# STM32H7S register map
File version: 1.3
CPU: CM7 r0p1, little endian, MPU, FPU, 4 interrupt priority bits
Registers are 32-bit, read-write, reset 0x0 unless marked. A register's access mark holds for its fields unless they carry their own. Offsets are from the block's base; [hi:lo] are bit positions; lines under a group give offsets from that group; {n}, {i} and the like mark numbered series; 'fields as' and 'values as' point back to an identical list; <NAME> marks a mode.

## HPDMA — High-performance direct memory access controller
Base 0x52000000
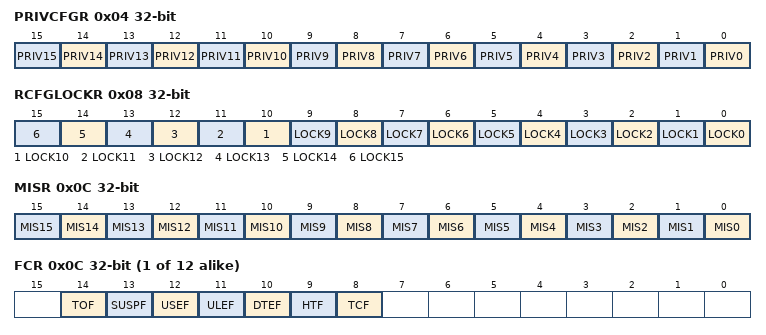
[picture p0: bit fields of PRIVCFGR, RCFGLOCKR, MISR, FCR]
0x04 PRIVCFGR — HPDMA privileged configuration register
  [n] PRIV{n} (n=0..15) — privileged state of channel x
0x08 RCFGLOCKR — HPDMA configuration lock register
  [n] LOCK{n} (n=0..15) — lock the configuration of HPDMA_PRIVCFGR.PRIVx until a global HPDMA reset This bit is cleared after reset and, once set, it cannot be reset until a global HPDMA reset.
0x0C MISR ro — HPDMA masked interrupt status register
  [n] MIS{n} (n=0..15) — masked interrupt status of channel x
{0x50+0x80*i} CH{i} (i=0..11) group — Channel cluster
  0x00 LBAR — HPDMA channel 0 linked-list base address register
    [31:16] LBA — linked-list base address of HPDMA channel x
  0x0C FCR wo — HPDMA channel 0 flag clear register
    [14] TOF — trigger overrun flag clear
    [13] SUSPF — completed suspension flag clear
    [12] USEF — user setting error flag clear
    [11] ULEF — update link transfer error flag clear
    [10] DTEF — data transfer error flag clear
    [9] HTF — half transfer flag clear
    [8] TCF — transfer complete flag clear
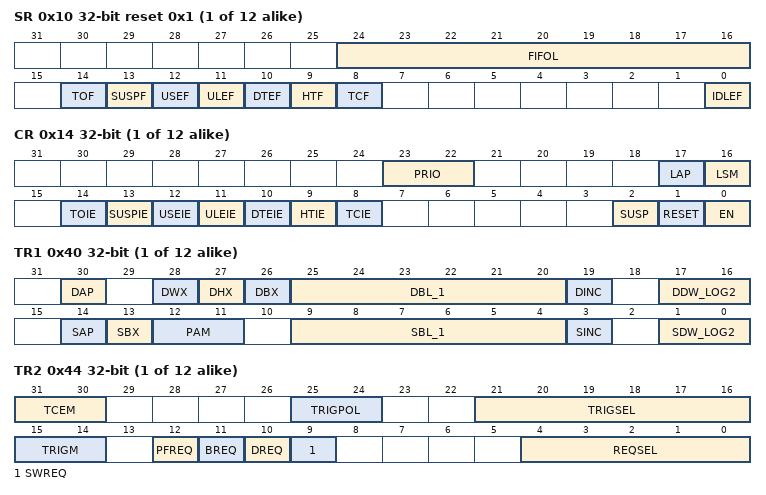
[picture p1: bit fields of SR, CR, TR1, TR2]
  0x10 SR ro reset 0x1 — HPDMA channel 0 status register
    [24:16] FIFOL — monitored FIFO level
    [14] TOF — trigger overrun flag
    [13] SUSPF — completed suspension flag
    [12] USEF — user setting error flag
    [11] ULEF — update link transfer error flag
    [10] DTEF — data transfer error flag
    [9] HTF — half transfer flag An half transfer event is either an half block transfer or an half 2D/repeated block transfer, depending on the transfer complete event mode (HPDMA_CxTR2.TCEM[1:0]). An half block transfer occurs when half of the bytes of the source block size (rounded up integer of HPDMA_CxBR1.BNDT[15:0]/2) has been transferred to the destination. An half 2D/repeated block transfer occurs when half of the repeated blocks (rounded up integer of (HPDMA_CxBR1.BRC[10:0]+1)/2)) has been transferred to the destination.
    [8] TCF — transfer complete flag A transfer complete event is either a block transfer complete, a 2D/repeated block transfer complete, a LLI transfer complete including the upload of the next LLI if any, or the full linked-list completion, depending on the transfer complete event mode (HPDMA_CxTR2.TCEM[1:0]).
    [0] IDLEF — idle flag This idle flag is de-asserted by hardware when the channel is enabled (HPDMA_CxCR.EN = 1) with a valid channel configuration (no USEF to be immediately reported). This idle flag is asserted after hard reset or by hardware when the channel is back in idle state (in suspended or disabled state).
  0x14 CR access per field — HPDMA channel 0 control register
    [23:22] PRIO rw — priority level of the channel x HPDMA transfer versus others Note: This bit must be written when EN = 0. This bit is read-only when EN = 1.
    [17] LAP rw — linked-list allocated port This bit is used to allocate the master port for the update of the HPDMA linked-list registers from the memory. Note: This bit must be written when EN=0. This bit is read-only when EN=1.
    [16] LSM rw — Link step mode First the (possible 1D/repeated) block transfer is executed as defined by the current internal register file until HPDMA_CxBR1.BNDT[15:0] = 0 and HPDMA_CxBR1.BRC[10:0] = 0 if present. Secondly the next linked-list data structure is conditionally uploaded from memory as defined by HPDMA_CxLLR. Then channel execution is completed. Note: This bit must be written when EN = 0. This bit is read-only when EN = 1.
    [14] TOIE rw — trigger overrun interrupt enable
    [13] SUSPIE rw — completed suspension interrupt enable
    [12] USEIE rw — user setting error interrupt enable
    [11] ULEIE rw — update link transfer error interrupt enable
    [10] DTEIE rw — data transfer error interrupt enable
    [9] HTIE rw — half transfer complete interrupt enable
    [8] TCIE rw — transfer complete interrupt enable
    [2] SUSP rw — suspend Writing 1 into the field RESET (bit 1) causes the hardware to de-assert this bit, whatever is written into this bit 2. Else: Software must write 1 in order to suspend an active channel (a channel with an ongoing HPDMA transfer over its master ports). The software must write 0 in order to resume a suspended channel, following the programming sequence detailed in Figure 158.
    [1] RESET wo — reset This bit is write only. Writing 0 has no impact. Writing 1 implies the reset of the following: the FIFO, the channel internal state, SUSP and EN bits (whatever is written receptively in bit 2 and bit 0). The reset is effective when the channel is in steady state, meaning one of the following: - active channel in suspended state (HPDMA_CxSR.SUSPF = 1 and HPDMA_CxSR.IDLEF = HPDMA_CxCR.EN = 1) - channel in disabled state (HPDMA_CxSR.IDLEF = 1 and HPDMA_CxCR.EN = 0). After writing a RESET, to continue using this channel, the user must explicitly reconfigure the channel including the hardware-modified configuration registers (HPDMA_CxBR1, HPDMA_CxSAR and HPDMA_CxDAR) before enabling again the channel (see the programming sequence in Figure 159).
    [0] EN rw — enable Writing 1 into the field RESET (bit 1) causes the hardware to de-assert this bit, whatever is written into this bit 0. Else: this bit is de-asserted by hardware when there is a transfer error (master bus error or user setting error) or when there is a channel transfer complete (channel ready to be configured, for example if LSM = 1 at the end of a single execution of the LLI). Else, this bit can be asserted by software. Writing 0 into this EN bit is ignored.
  0x40 TR1 — HPDMA channel 0 transfer register 1
    [30] DAP — destination allocated port This bit is used to allocate the master port for the destination transfer Note: This bit must be written when EN = 0. This bit is read-only when EN = 1.
    [28] DWX — destination word exchange If the destination data size is not a double-word, this bit is ignored. If the destination data size is a double-word and if destination bus is AXI (DAP = 0):
    [27] DHX — destination half-word exchange If the destination data size is shorter than a word, this bit is ignored. If the destination data size is a word or double-word and if destination bus is AXI (DAP = 0):
    [26] DBX — destination byte exchange If the destination data size is a byte, this bit is ignored. If the destination data size is not a byte:
    [25:20] DBL_1 — destination burst length minus 1, between 0 and 63 The burst length unit is one data named beat within a burst. If DBL_1[5:0] =0 , the burst can be named as single. Each data/beat has a width defined by the destination data width DDW_LOG2[1:0]. Note: If a burst transfer crossed a 1- or 4-Kbyte address boundary on respectively an AHB or AXI transfer, the HPDMA modifies and shortens the programmed burst into singles or bursts of lower length, to be compliant with the AHB/AXI protocol. Note: If the burst length exceeds 16 on an AHB transfer, or if the burst on an AXI transfer is both with fixed addressing (DINC = 0) and with a burst length which exceeds 16, the HPDMA modifies and shortens the programmed burst into bursts of lower length, to be compliant with the AHB or AXI protocol. Note: If a burst transfer is of length greater than the FIFO size of the channel x, the HPDMA modifies and shortens the programmed burst into singles or bursts of lower length, to be compliant with the FIFO size. Transfer performance is lower, with HPDMA re-arbitration between effective and lower singles/bursts, but the data integrity is guaranteed.
    [19] DINC — destination incrementing burst The destination address, pointed by HPDMA_CxDAR, is kept constant after a burst beat/single transfer, or is incremented by the offset value corresponding to a contiguous data after a burst beat/single transfer.
    [17:16] DDW_LOG2 — binary logarithm of the destination data width of a burst, in bytes if DAP = 1, user setting error reported and no transfer issued Note: A burst with a double-word data width must be allocated to the AXI master port, else a user setting error is reported and none transfer is issued. Note: A destination burst transfer must have an aligned address with its data width (start address HPDMA_CxDAR[2:0] and address offset HPDMA_CxTR3.DAO[2:0], versus DDW_LOG2[1:0]). Otherwise a user setting error is reported and no transfer is issued. Note: When configured in packing mode (PAM[1] = 1 and destination data width different from source data width), a source block size must be a multiple of the destination data width (see HPDMA_CxBR1.BNDT[2:0] vs DDW_LOG2[1:0]). Else a user setting error is reported and none transfer is issued.
    [14] SAP — source allocated port This bit is used to allocate the master port for the source transfer Note: This bit must be written when EN = 0. This bit is read-only when EN = 1.
    [13] SBX — source byte exchange within the unaligned half-word of each source word If the source data width is shorter than a word, this bit is ignored. If the source data width is a word or a double-word, and if source bus is AXI (SAP = 0):
    [12:11] PAM — padding/alignment mode If DDW_LOG2[1:0] = SDW_LOG2[1:0]: if the data width of a burst destination transfer is equal to the data width of a burst source transfer, these bits are ignored. Else, in the following enumerated values, the condition PAM_1 is when destination data width is higher that source data width, and the condition PAM_2 is when destination data width is higher than source data width. Note: If the transfer from the source peripheral is configured with peripheral flow-control mode (SWREQ = 0 and PFREQ = 1 and DREQ = 0), and if the destination data width > the source data width, packing is not supported.
    [9:4] SBL_1 — source burst length minus 1, between 0 and 63 The burst length unit is one data named beat within a burst. If SBL_1[5:0] =0 , the burst can be named as single. Each data/beat has a width defined by the destination data width SDW_LOG2[1:0]. Note: If a burst transfer crossed a 1- or 4-Kbyte address boundary on respectively an AHB or an AXI transfer, the HPDMA modifies and shortens the programmed burst into singles or bursts of lower length, to be compliant with the AHB protocol. Note: If the burst length exceeds 16 on a AHB transfer, or if the burst on a AXI transfer is both with fixed addressing (SINC=0) and with a burst length which exceeds 16, the HPDMA modifies and shortens the programmed burst into singles or bursts of lower length, to be compliant with the FIFO size. Transfer performance is lower, with HPDMA re-arbitration between effective and lower singles/bursts, but the data integrity is guaranteed.
    [3] SINC — source incrementing burst The source address, pointed by HPDMA_CxSAR, is kept constant after a burst beat/single transfer or is incremented by the offset value corresponding to a contiguous data after a burst beat/single transfer.
    [1:0] SDW_LOG2 — binary logarithm of the source data width of a burst in bytes if SAP = 1, user setting error reported and no transfer issued Note: A burst with a double-word data width must be allocated to the AXI master port, else a user setting error is reported and none transfer is issued. A source block size must be a multiple of the source data width (HPDMA_CxBR1.BNDT[2:0] versus SDW_LOG2[1:0]). Otherwise, a user setting error is reported and no transfer is issued. Note: A source burst transfer must have an aligned address with its data width (start address HPDMA_CxSAR[2:0] versus SDW_LOG2[1:0]). Otherwise, a user setting error is reported and none transfer is issued.
  0x44 TR2 — HPDMA channel 0 transfer register 2
    [31:30] TCEM — transfer complete event mode These bits define the transfer granularity for the transfer complete and half transfer complete events generation. Note: If the initial LLI<sub>0 </sub>data transfer is null/void (directly programmed by the internal register file with HPDMA_CxBR1.BNDT[15:0] = 0), then neither the complete transfer event nor the half transfer event is generated. Note: If the initial LLI<sub>0 </sub>data transfer is null/void (directly programmed by the internal register file with HPDMA_CxBR1.BNDT[15:0] = 0), then neither the complete transfer event nor the half transfer event is generated. Note: If the initial LLI<sub>0 </sub>data transfer is null/void (directly programmed by the internal register file with HPDMA_CxBR1.BNDT[15:0] = 0), then the half transfer event is not generated, and the transfer complete event is generated when is completed the loading of the LLI<sub>1</sub>.
    [25:24] TRIGPOL — trigger event polarity These bits define the polarity of the selected trigger event input defined by TRIGSEL[5:0].
    [21:16] TRIGSEL — trigger event input selection These bits select the trigger event input of the HPDMA transfer (as per Section 27.3.6), with an active trigger event if TRIGPOL[1:0] different from 00.
    [15:14] TRIGM — trigger mode These bits define the transfer granularity for its conditioning by the trigger. If the channel x is enabled (HPDMA_CxCR.EN asserted) with TRIGPOL[1:0] = 00 or 11, these TRIGM[1:0] bits are ignored. Else, an HPDMA transfer is conditioned by at least one trigger hit: first burst read of a 2D/repeated block transfer is conditioned by one hit trigger. If the peripheral is programmed as a source (DREQ = 0) of the LLI data transfer, each programmed burst read is conditioned. If the peripheral is programmed as a destination (DREQ = 1) of the LLI data transfer, each programmed burst write is conditioned. The first memory burst read of a (possibly 2D/repeated) block, also named as the first ready FIFO-based source burst, is gated by the occurrence of both the hardware request and the first trigger hit. The HPDMA monitoring of a trigger for channel x is started when the channel is enabled/loaded with a new active trigger configuration: rising or falling edge on a selected trigger (TRIGPOL[1:0] = 01 or respectively TRIGPOL[1:0] = 10). The monitoring of this trigger is kept active during the triggered and uncompleted (data or link) transfer; and if a new trigger is detected then, this hit is internally memorized to grant the next transfer, as long as the defined rising or falling edge is not modified, and the TRIGSEL[5:0] is not modified, and the channel is enabled. Transferring a next LLI<sub>n+1</sub> that updates the HPDMA_CxTR2 with a new value for any of TRIGSEL[5:0] or TRIGPOL[1:0], resets the monitoring, trashing the memorized hit of the formerly defined LLI<sub>n </sub>trigger. After a first new trigger hit<sub>n+1</sub> is memorized, if another second trigger hit<sub>n+2</sub> is detected and if the hit<sub>n</sub> triggered transfer is still not completed, hit<sub>n+2 </sub>is lost and not memorized.memorized. A trigger overrun flag is reported (HPDMA_CxSR.TOF =1 ), and an interrupt is generated if enabled (HPDMA_CxCR.TOIE = 1). The channel is not automatically disabled by hardware due to a trigger overrun. Note: When the source block size is not a multiple of the source burst size and is a multiple of the source data width, then the last programmed source burst is not completed and is internally shorten to match the block size. In this case, if TRIGM[1:0] = 11 and (SWREQ =1 or (SWREQ = 0 and DREQ =0 )), the shortened burst transfer (by singles or/and by bursts of lower length) is conditioned once by the trigger. Note: When the programmed destination burst is internally shortened by singles or/and by bursts of lower length (versus FIFO size, versus block size, 1/4-Kbyte boundary address crossing maximum burst length vs AHB/AXI protocol): if the trigger is conditioning the programmed destination burst (if TRIGM[1:0] = 11 and SWREQ = 0 and DREQ = 1), this shortened destination burst transfer is conditioned once by the trigger.
    [12] PFREQ — Hardware request in peripheral flow control mode Important: If a given channel x is not implemented with this feature, this bit is reserved and PFREQ is not present (see Section 27.3.5 for the list of the implemented channels with this feature. If the channel x is activated (HPDMA_CxCR.EN asserted) with SWREQ = 1 (software request for a memory-to-memory transfer), this bit is ignored. Else: Note: In peripheral flow control mode, there are the following restrictions: Note: - no 2D/repeated block support (HPDMA_CxBR1.BRC[10:0] must be set to 0 if present) Note: - the peripheral must be set as the source of the transfer (DREQ = 0). Note: - data packing to a wider destination width is not supported (if destination width > source data width, HPDMA_CxTR1.PAM[1] must be set to 0). Note: - HPDMA_CxBR1.BNDT[15:0] must be set as a multiple of the source (peripheral) burst size.
    [11] BREQ — Block hardware request If the channel x is activated (HPDMA_CxCR.EN asserted) with SWREQ = 1 (software request for a memory-to-memory transfer), this bit is ignored. Else:
    [10] DREQ — destination hardware request This bit is ignored if channel x is activated (HPDMA_CxCR.EN asserted) with SWREQ = 1 (software request for a memory-to-memory transfer). Else: Note: If the channel x is activated (HPDMA_CxCR.EN is asserted) with SWREQ = 0 and PFREQ = 1 (peripheral hardware request with peripheral flow-control mode), any software assertion to this DREQ bit is ignored: in peripheral flow-control mode, only a peripheral-to-memory transfer is supported.
    [9] SWREQ — software request This bit is internally taken into account when HPDMA_CxCR.EN is asserted.
    [4:0] REQSEL — hardware request selection These bits are ignored if channel x is activated (HPDMA_CxCR.EN asserted) with SWREQ = 1 (software request for a memory-to-memory transfer). Else, the selected hardware request is internally taken into account as per Section 27.3.3. The user must not assign a same input hardware request (same REQSEL[4:0] value) to different active HPDMA channels (HPDMA_CxCR.EN = 1 and HPDMA_CxTR2.SWREQ = 0 for these channels). The HPDMA is not intended to hardware support the case of simultaneous enabled channels incorrectly configured with a same hardware peripheral request signal, and there is no user setting error reporting.
  0x48 BR1 — HPDMA channel 0 block register 1
    [15:0] BNDT — block number of data bytes to transfer from the source Block size transferred from the source. When the channel is enabled, this field becomes read-only and is decremented, indicating the remaining number of data items in the current source block to be transferred. BNDT[15:0] is programmed in number of bytes, maximum source block size is 64 Kbytes -1. Once the last data transfer is completed (BNDT[15:0] = 0): - if HPDMA_CxLLR.UB1 = 1, this field is updated by the LLI in the memory. - if HPDMA_CxLLR.UB1 = 0 and if there is at least one non null Uxx update bit, this field is internally restored to the programmed value. - if all HPDMA_CxLLR.Uxx = 0 and if HPDMA_CxLLR.LA[15:0] = 0, this field is internally restored to the programmed value (infinite/continuous last LLI). - if HPDMA_CxLLR = 0, this field is kept as zero following the last LLI data transfer. Note: A non-null source block size must be a multiple of the source data width (BNDT[2:0] versus HPDMA_CxTR1.SDW_LOG2[1:0]). Else a user setting error is reported and no transfer is issued. Note: When configured in packing mode (HPDMA_CxTR1.PAM[1] = 1 and destination data width different from source data width), a non-null source block size must be a multiple of the destination data width (BNDT[2:0] versus HPDMA_CxTR1.DDW_LOG2[1:0]). Else a user setting error is reported and no transfer is issued.
  0x4C SAR — HPDMA channel 0 source address register
    [31:0] SA — source address This field is the pointer to the address from which the next data is read. During the channel activity, depending on the source addressing mode (HPDMA_CxTR1.SINC), this field is kept fixed or incremented by the data width (HPDMA_CxTR1.SDW_LOG2[1:0]) after each burst source data, reflecting the next address from which data is read. During the channel activity, this address is updated after each completed source burst, consequently to: the programmed source burst; either in fixed addressing mode or in contiguous-data incremented mode. If contiguously incremented (HPDMA_CxTR1.SINC = 1), then the additional address offset value is the programmed burst size, as defined by HPDMA_CxTR1.SBL_1[5:0] and HPDMA_CxTR1.SDW_LOG2[21:0] the additional source incremented/decremented offset value as programmed by HPDMA_CxBR1.SDEC and HPDMA_CxTR3.SAO[12:0] once/if completed source block transfer, for a channel x with 2D addressing capability (x = 12 to 15). additional block repeat source incremented/decremented offset value as programmed by HPDMA_CxBR1.BRSDEC and HPDMA_CxBR2.BRSAO[15:0] In linked-list mode, after a LLI data transfer is completed, this register is automatically updated by HPDMA from the memory, provided the LLI is set with HPDMA_CxLLR.USA = 1. Note: A source address must be aligned with the programmed data width of a source burst (SA[2:0] versus HPDMA_CxTR1.SDW_LOG2[1:0]). Else, a user setting error is reported and no transfer is issued. Note: When the source block size is not a multiple of the source burst size and is a multiple of the source data width, the last programmed source burst is not completed and is internally shorten to match the block size. In this case, the additional HPDMA_CxTR3.SAO[12:0] is not applied.
  0x50 DAR — HPDMA channel 0 destination address register
    [31:0] DA — destination address This field is the pointer to the address from which the next data is written. During the channel activity, depending on the destination addressing mode (HPDMA_CxTR1.DINC), this field is kept fixed or incremented by the data width (HPDMA_CxTR1.DDW_LOG2[21:0]) after each burst destination data, reflecting the next address from which data is written. During the channel activity, this address is updated after each completed destination burst, consequently to: the programmed destination burst; either in fixed addressing mode or in contiguous-data incremented mode. If contiguously incremented (HPDMA_CxTR1.DINC = 1), then the additional address offset value is the programmed burst size, as defined by HPDMA_CxTR1.DBL_1[5:0] and HPDMA_CxTR1.DDW_LOG2[1:0] the additional destination incremented/decremented offset value as programmed by HPDMA_CxBR1.DDEC and HPDMA_CxTR3.DAO[12:0] once/if completed destination block transfer, for a channel x with 2D addressing capability (x = 12 to 15), the additional block repeat destination incremented/decremented offset value as programmed by HPDMA_CxBR1.BRDDEC and HPDMA_CxBR2.BRDAO[15:0] In linked-list mode, after a LLI data transfer is completed, this register is automatically updated by the HPDMA from the memory, provided the LLI is set with HPDMA_CxLLR.UDA = 1. Note: A destination address must be aligned with the programmed data width of a destination burst (DA[2:0] versus HPDMA_CxTR1.DDW_LOG2[1:0]). Else, a user setting error is reported and no transfer is issued.
  0x7C LLR — HPDMA channel 0 linked-list address register
    [31] UT1 — Update HPDMA_CxTR1 from memory This bit controls the update of HPDMA_CxTR1 from the memory during the link transfer.
    [30] UT2 — Update HPDMA_CxTR2 from memory This bit controls the update of HPDMA_CxTR2 from the memory during the link transfer.
    [29] UB1 — Update HPDMA_CxBR1 from memory This bit controls the update of HPDMA_CxBR1 from the memory during the link transfer. If UB1 = 0 and if HPDMA_CxLLR different from 0, the linked-list is not completed. HPDMA_CxBR1.BNDT[15:0] is then restored to the programmed value after data transfer is completed and before the link transfer.
    [28] USA — update HPDMA_CxSAR from memory This bit controls the update of HPDMA_CxSAR from the memory during the link transfer.
    [27] UDA — Update HPDMA_CxDAR register from memory This bit is used to control the update of HPDMA_CxDAR from the memory during the link transfer.
    [16] ULL — Update HPDMA_CxLLR register from memory This bit is used to control the update of HPDMA_CxLLR from the memory during the link transfer.
    [15:2] LA — pointer (16-bit low-significant address) to the next linked-list data structure If UT1 = UT2 = UB1 = USA = UDA = ULL = 0 and if LA[15:20] = 0, the current LLI is the last one. The channel transfer is completed without any update of the linked-list HPDMA register file. Else, this field is the pointer to the memory address offset from which the next linked-list data structure is automatically fetched from, once the data transfer is completed, in order to conditionally update the linked-list HPDMA internal register file (HPDMA_CxTR1, HPDMA_CxTR2, HPDMA_CxBR1, HPDMA_CxSAR, HPDMA_CxDAR and HPDMA_CxLLR). Note: The user must program the pointer to be 32-bit aligned. The two low-significant bits are write ignored.
{0x50+0x80*i} CH2D{i} (i=12..15) group — Extended channel cluster
  0x00 LBAR — HPDMA channel 12 linked-list base address register
    [31:16] LBA — linked-list base address of HPDMA channel x
  0x0C FCR wo — HPDMA channel 12 flag clear register
    fields as CH0.FCR
  0x10 SR ro reset 0x1 — HPDMA channel 12 status register
    fields as CH0.SR
  0x14 CR access per field — HPDMA channel 12 control register
    fields as CH0.CR
  0x40 TR1 — HPDMA channel 12 transfer register 1
    fields as CH0.TR1
  0x44 TR2 — HPDMA channel 12 transfer register 2
    fields as CH0.TR2
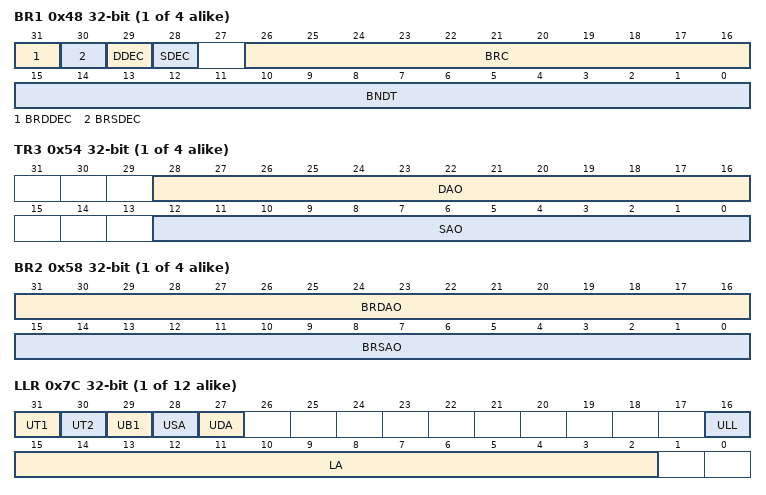
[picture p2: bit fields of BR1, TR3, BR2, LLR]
  0x48 BR1 — HPDMA channel 12 alternate block register 1
    [31] BRDDEC — Block repeat destination address decrement Note: On top of this increment/decrement (depending on BRDDEC), HPDMA_CxDAR is in the same time also updated by the increment/decrement (depending on DDEC) of the HPDMA_CxTR3.DAO value, as it is usually done at the end of each programmed burst transfer.
    [30] BRSDEC — Block repeat source address decrement Note: On top of this increment/decrement (depending on BRSDEC), HPDMA_CxSAR is in the same time also updated by the increment/decrement (depending on SDEC) of the HPDMA_CxTR3.SAO value, as it is done after any programmed burst transfer.
    [29] DDEC — destination address decrement
    [28] SDEC — source address decrement
    [26:16] BRC — Block repeat counter This field contains the number of repetitions of the current block (0 to 2047). When the channel is enabled, this field becomes read-only. After decrements, this field indicates the remaining number of blocks, excluding the current one. This counter is hardware decremented for each completed block transfer. Once the last block transfer is completed (BRC[10:0] = BNDT[15:0] = 0): If HPDMA_CxLLR.UB1 = 1, all HPDMA_CxBR1 fields are updated by the next LLI in the memory. If HPDMA_CxLLR.UB1 = 0 and if there is at least one not null Uxx update bit, this field is internally restored to the programmed value. if all HPDMA_CxLLR.Uxx = 0 and if HPDMA_CxLLR.LA[15:0] different from 0, this field is internally restored to the programmed value (infinite/continuous last LLI). if HPDMA_CxLLR = 0, this field is kept as zero following the last LLI and data transfer.
    [15:0] BNDT — block number of data bytes to transfer from the source Block size transferred from the source. When the channel is enabled, this field becomes read-only and is decremented, indicating the remaining number of data items in the current source block to be transferred. BNDT[15:0] is programmed in number of bytes, maximum source block size is 64 Kbytes -1. Once the last data transfer is completed (BNDT[15:0] = 0): - if HPDMA_CxLLR.UB1 = 1, this field is updated by the LLI in the memory. - if HPDMA_CxLLR.UB1 = 0 and if there is at least one not null Uxx update bit, this field is internally restored to the programmed value. - if all HPDMA_CxLLR.Uxx = 0 and if HPDMA_CxLLR.LA[15:0] different from 0, this field is internally restored to the programmed value (infinite/continuous last LLI). - if HPDMA_CxLLR = 0, this field is kept as zero following the last LLI data transfer. Note: A non-null source block size must be a multiple of the source data width (BNDT[2:0] versus HPDMA_CxTR1.SDW_LOG2[1:0]). Else a user setting error is reported and no transfer is issued. Note: When configured in packing mode (HPDMA_CxTR1.PAM[1]=1 and destination data width different from source data width), a non-null source block size must be a multiple of the destination data width (BNDT[2:0] versus HPDMA_CxTR1.DDW_LOG2[1:0]). Else a user setting error is reported and no transfer is issued.
  0x4C SAR — HPDMA channel 12 source address register
    fields as CH0.SAR
  0x50 DAR — HPDMA channel 12 destination address register
    fields as CH0.DAR
  0x54 TR3 — HPDMA channel 12 transfer register 3
    [28:16] DAO — destination address offset increment The destination address, pointed by HPDMA_CxDAR, is incremented or decremented (depending on HPDMA_CxBR1.DDEC) by this offset DAO[12:0] for each programmed destination burst. This offset is not including and is added to the programmed burst size when the completed burst is addressed in incremented mode (HPDMA_CxTR1.DINC = 1). Note: A destination address offset must be aligned with the programmed data width of a destination burst (DAO[2:0] versus HPDMA_CxTR1.DDW_LOG2[1:0]). Else, a user setting error is reported and no transfer is issued.
    [12:0] SAO — source address offset increment The source address, pointed by HPDMA_CxSAR, is incremented or decremented (depending on HPDMA_CxBR1.SDEC) by this offset SAO[12:0] for each programmed source burst. This offset is not including and is added to the programmed burst size when the completed burst is addressed in incremented mode (HPDMA_CxTR1.SINC = 1). Note: A source address offset must be aligned with the programmed data width of a source burst (SAO[2:0] versus HPDMA_CxTR1.SDW_LOG2[1:0]). Else a user setting error is reported and none transfer is issued. Note: When the source block size is not a multiple of the destination burst size and is a multiple of the source data width, then the last programmed source burst is not completed and is internally shorten to match the block size. In this case, the additional HPDMA_CxTR3.SAO[12:0] is not applied.
  0x58 BR2 — HPDMA channel 12 block register 2
    [31:16] BRDAO — Block repeated destination address offset For a channel with 2D addressing capability, this field is used to update (by addition or subtraction depending on HPDMA_CxBR1.BRDDEC) the current destination address (HPDMA_CxDAR) at the end of a block transfer. A block repeated destination address offset must be aligned with the programmed data width of a destination burst (BRDAO[2:0] versus HPDMA_CxTR1.DDW_LOG2[1:0]). Else a user setting error is reported and no transfer is issued. Note: BRDAO[15:0] must be set to 0 in peripheral flow-control mode (if HPDMA_CxTR2.PFREQ=1).
    [15:0] BRSAO — Block repeated source address offset For a channel with 2D addressing capability, this field is used to update (by addition or subtraction depending on HPDMA_CxBR1.BRSDEC) the current source address (HPDMA_CxSAR) at the end of a block transfer. A block repeated source address offset must be aligned with the programmed data width of a source burst (BRSAO[2:0] versus HPDMA_CxTR1.SDW_LOG2[1:0]). Else a user setting error is reported and no transfer is issued. Note: BRSAO[15:0] must be set to 0 in peripheral flow-control mode (if HPDMA_CxTR2.PFREQ=1).
  0x7C LLR — HPDMA channel 12 alternate linked-list address register
    [31] UT1 — Update HPDMA_CxTR1 from memory This bit controls the update of HPDMA_CxTR1 from the memory during the link transfer.
    [30] UT2 — Update HPDMA_CxTR2 from memory This bit controls the update of HPDMA_CxTR2 from the memory during the link transfer.
    [29] UB1 — Update HPDMA_CxBR1 from memory This bit controls the update of HPDMA_CxBR1 from the memory during the link transfer. If UB1 = 0 and if HPDMA_CxLLR different from 0, the linked-list is not completed. HPDMA_CxBR1.BNDT[15:0] is then restored to the programmed value after data transfer is completed and before the link transfer.
    [28] USA — update HPDMA_CxSAR from memory This bit controls the update of HPDMA_CxSAR from the memory during the link transfer.
    [27] UDA — Update HPDMA_CxDAR register from memory This bit is used to control the update of HPDMA_CxDAR from the memory during the link transfer.
    [26] UT3 — Update HPDMA_CxTR3 from memory This bit controls the update of HPDMA_CxTR3 from the memory during the link transfer.
    [25] UB2 — Update HPDMA_CxBR2 from memory This bit controls the update of HPDMA_CxBR2 from the memory during the link transfer.
    [16] ULL — Update HPDMA_CxLLR register from memory This bit is used to control the update of HPDMA_CxLLR from the memory during the link transfer.
    [15:2] LA — pointer (16-bit low-significant address) to the next linked-list data structure If UT1 = UT2 = UB1 = USA = UDA = ULL = 0 and if LA[15:20] = 0, the current LLI is the last one. The channel transfer is completed without any update of the linked-list HPDMA register file. Else, this field is the pointer to the memory address offset from which the next linked-list data structure is automatically fetched from, once the data transfer is completed, in order to conditionally update the linked-list HPDMA internal register file (HPDMA_CxTR1, HPDMA_CxTR2, HPDMA_CxBR1, HPDMA_CxSAR, HPDMA_CxDAR and HPDMA_CxLLR). Note: The user must program the pointer to be 32-bit aligned. The two low-significant bits are write ignored.
